# CY8C5888AXI_LP096 register map
File version: 0.1
CY8C58LP
Registers are 8-bit, read-write, no defined reset value unless marked. A register's access mark holds for its fields unless they carry their own. Offsets are from the block's base; lines under a group give offsets from that group; [hi:lo] are bit positions; {n}, {i} and the like mark numbered series; 'fields as' and 'values as' point back to an identical list; <NAME> marks a mode.

## Memory map
0x00000000 UART
0x4000646E SWITCHES
0x40006478 LEDS
0x4000647E ControlRegDisp

## ControlRegDisp
Base 0x4000647E
0x00 ControlRegDisp_CONTROL_REG

## UART
Base 0x00000000
0x4000642D RX_UART_RX_ADDRESS1 — RX Address1 Register
0x4000643D RX_UART_RX_ADDRESS2 — RX Address2 Register
0x4000644B TX_UART_TX_DATA — TX Data Register
0x4000644D RX_UART_RX_DATA — RX Data Register
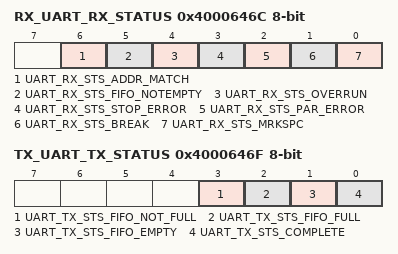
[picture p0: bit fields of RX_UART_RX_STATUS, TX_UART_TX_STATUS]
0x4000646C RX_UART_RX_STATUS — RX status register
  [6] UART_RX_STS_ADDR_MATCH ro, [5] UART_RX_STS_FIFO_NOTEMPTY ro, [4] UART_RX_STS_OVERRUN ro, [3] UART_RX_STS_STOP_ERROR ro, [2] UART_RX_STS_PAR_ERROR ro, [1] UART_RX_STS_BREAK ro, [0] UART_RX_STS_MRKSPC ro
0x4000646F TX_UART_TX_STATUS — TX status register
  [3] UART_TX_STS_FIFO_NOT_FULL ro, [2] UART_TX_STS_FIFO_FULL ro, [1] UART_TX_STS_FIFO_EMPTY ro, [0] UART_TX_STS_COMPLETE ro

## SWITCHES
Base 0x4000646E
0x00 SWITCHES_STATUS_REG
0x20 SWITCHES_MASK_REG
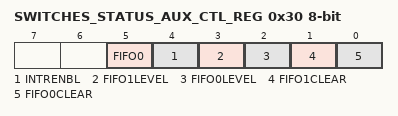
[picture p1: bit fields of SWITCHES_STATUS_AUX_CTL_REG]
0x30 SWITCHES_STATUS_AUX_CTL_REG
  [5] FIFO0 — FIFO0 clear
    1=ENABLED (Enable counter); 0=DISABLED (Disable counter)
  [4] INTRENBL — Enables or disables the Interrupt
    1=ENABLED (Interrupt enabled); 0=DISABLED (Interrupt disabled)
  [3] FIFO1LEVEL — FIFO level
    1=ENABLED (FIFO LVL: input mode: FIFO at least 1/2 empty; output mode: FIFO at least 1/2 full); 0=DISABLED (FIFO LVL: input mode: FIFO not full; output mode: FIFO not empty)
  [2] FIFO0LEVEL — FIFO level
    values as FIFO1LEVEL
  [1] FIFO1CLEAR — FIFO clear
    1=ENABLED (Clear FIFO state); 0=DISABLED (Normal FIFO operation)
  [0] FIFO0CLEAR — FIFO clear
    values as FIFO1CLEAR

## LEDS
Base 0x40006478
Registers as ControlRegDisp (with ControlRegDisp read as LEDS).
